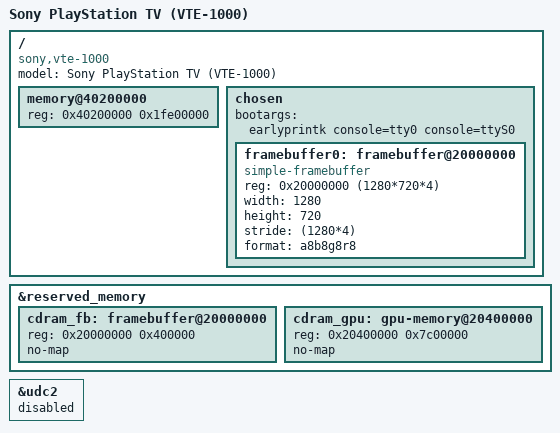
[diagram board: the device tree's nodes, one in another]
// SPDX-License-Identifier: GPL-2.0
/*
 * Device Tree Source for the PlayStation TV (VTE-1000)
 */

/dts-v1/;

#include "vita.dtsi"

/ {
	model = "Sony PlayStation TV (VTE-1000)";
	compatible = "sony,vte-1000", "sony,vita", "vita,vita";

	/*
	 * 512 MiB LPDDR2 at 0x40000000 [WIKI Physical_Memory].
	 * The first 2 MiB (0x40000000-0x401FFFFF) are the secure world's.
	 */
	memory@40200000 {
		device_type = "memory";
		reg = <0x40200000 0x1fe00000>;
	};

	chosen {
		bootargs = "earlyprintk console=tty0 console=ttyS0";

		/* Set up by the boot loader in CDRAM (0x20000000, 128 MiB) */
		framebuffer0: framebuffer@20000000 {
			compatible = "simple-framebuffer";
			reg = <0x20000000 (1280*720*4)>;
			width = <1280>;
			height = <720>;
			stride = <(1280*4)>;
			format = "a8b8g8r8";
			status = "okay";
		};
	};
};

&reserved_memory {
	/* The boot loader's 1280x720x4 framebuffer, rounded up to 4 MiB */
	cdram_fb: framebuffer@20000000 {
		reg = <0x20000000 0x400000>;
		no-map;
	};

	/* The rest of CDRAM: the GPU's buffer objects */
	cdram_gpu: gpu-memory@20400000 {
		reg = <0x20400000 0x7c00000>;
		no-map;
	};
};

/* udcd leaves bus 2 alone on the PlayStation TV (udcd.skprx 0x810082a0). */
&udc2 {
	status = "disabled";
};
